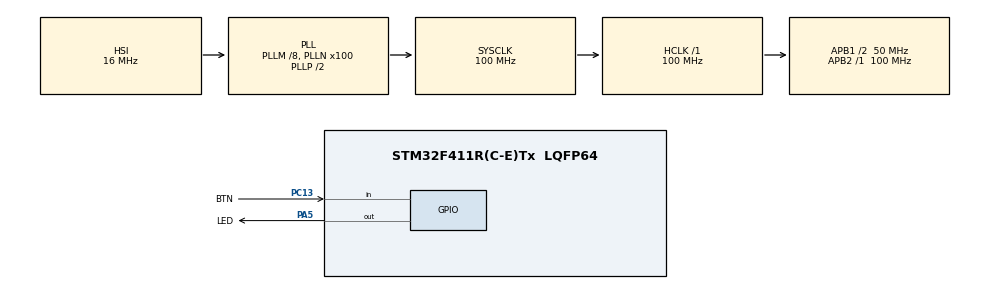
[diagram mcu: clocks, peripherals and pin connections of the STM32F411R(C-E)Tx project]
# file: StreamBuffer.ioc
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FREERTOS.Tasks01=defaultTask,24,128,StartDefaultTask,Default,NULL,Dynamic,NULL,NULL
FREERTOS.configUSE_NEWLIB_REENTRANT=1
Mcu.Family=STM32F4
Mcu.Name=STM32F411R(C-E)Tx
Mcu.Package=LQFP64
NVIC.PriorityGroup=NVIC_PRIORITYGROUP_4
NVIC.TIM1_UP_TIM10_IRQn=true\:15\:0\:false\:false\:true\:false\:false\:true\:true
NVIC.TimeBase=TIM1_UP_TIM10_IRQn
NVIC.TimeBaseIP=TIM1
PA13.Mode=Serial_Wire
PA13.Signal=SYS_JTMS-SWDIO
PA14.Mode=Serial_Wire
PA14.Signal=SYS_JTCK-SWCLK
PA5.GPIO_Label=LED
PA5.Signal=GPIO_Output
PC13-ANTI_TAMP.GPIO_Label=BTN
PC13-ANTI_TAMP.Signal=GPIO_Input
ProjectManager.HeapSize=0x200
ProjectManager.StackSize=0x400
ProjectManager.TargetToolchain=STM32CubeIDE
RCC.48MHZClocksFreq_Value=50000000
RCC.AHBFreq_Value=100000000
RCC.APB1CLKDivider=RCC_HCLK_DIV2
RCC.APB1Freq_Value=50000000
RCC.APB1TimFreq_Value=100000000
RCC.APB2Freq_Value=100000000
RCC.APB2TimFreq_Value=100000000
RCC.CortexFreq_Value=100000000
RCC.HCLKFreq_Value=100000000
RCC.HSE_VALUE=25000000
RCC.HSI_VALUE=16000000
RCC.LSE_VALUE=32768
RCC.PLLM=8
RCC.PLLN=100
RCC.SYSCLKFreq_VALUE=100000000
RCC.SYSCLKSource=RCC_SYSCLKSOURCE_PLLCLK
RCC.VCOOutputFreq_Value=200000000
VP_FREERTOS_VS_CMSIS_V2.Mode=CMSIS_V2
VP_SYS_VS_tim1.Mode=TIM1
board=custom

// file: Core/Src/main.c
/* USER CODE BEGIN Header */
/**
  ******************************************************************************
  * @file           : main.c
  * @brief          : Main program body
  ******************************************************************************
  * @attention
  *
  * Copyright (c) 2025 STMicroelectronics.
  * All rights reserved.
  *
  * This software is licensed under terms that can be found in the LICENSE file
  * in the root directory of this software component.
  * If no LICENSE file comes with this software, it is provided AS-IS.
  *
  ******************************************************************************
  */
/* USER CODE END Header */
#include "main.h"
#include "cmsis_os.h"

/* USER CODE BEGIN Includes */
#include <string.h>
#include <stdio.h>
#include "stream_buffer.h"
/* USER CODE END Includes */

/* Definitions for defaultTask */

/* USER CODE BEGIN PV */
TaskHandle_t task1_handle;
TaskHandle_t task2_handle;
StreamBufferHandle_t sb_handle_task1_to_task2;
StreamBufferHandle_t sb_handle_task2_to_task1;
char task1_buffer[15];
char task2_buffer[15];
uint8_t task1_sended_byte;
uint8_t task1_received_byte;
uint8_t task2_sended_byte;
uint8_t task2_received_byte;

void Task1(void *param);
void Task2(void *param);
/* USER CODE END PV */

void SystemClock_Config(void);
static void MX_GPIO_Init(void);

/* USER CODE BEGIN 0 */
uint8_t cnt = 0;
/* USER CODE END 0 */

int main(void)
{

  /* MCU Configuration--------------------------------------------------------*/

  /* Reset of all peripherals, Initializes the Flash interface and the Systick. */
  HAL_Init();

  /* Configure the system clock */
  SystemClock_Config();

  /* Initialize all configured peripherals */
  MX_GPIO_Init();

  /* Init scheduler */
  osKernelInitialize();

  /* Create the thread(s) */

  /* USER CODE BEGIN RTOS_THREADS */
  /* add threads, ... */

  xTaskCreate(Task1, "Task1", 128, NULL, 1, &task1_handle);
  xTaskCreate(Task2, "Task2", 128, NULL, 2, &task2_handle);
  /* USER CODE END RTOS_THREADS */

  /* Start scheduler */
  vTaskStartScheduler();
  /* We should never get here as control is now taken by the scheduler */

  /* Infinite loop */
  while (1)
  {

  }
}

void SystemClock_Config(void)
{
  RCC_OscInitTypeDef RCC_OscInitStruct = {0};
  RCC_ClkInitTypeDef RCC_ClkInitStruct = {0};

  /** Configure the main internal regulator output voltage
  */
  __HAL_RCC_PWR_CLK_ENABLE();
  __HAL_PWR_VOLTAGESCALING_CONFIG(PWR_REGULATOR_VOLTAGE_SCALE1);

  /** Initializes the RCC Oscillators according to the specified parameters
  * in the RCC_OscInitTypeDef structure.
  */
  RCC_OscInitStruct.OscillatorType = RCC_OSCILLATORTYPE_HSI;
  RCC_OscInitStruct.HSIState = RCC_HSI_ON;
  RCC_OscInitStruct.HSICalibrationValue = RCC_HSICALIBRATION_DEFAULT;
  RCC_OscInitStruct.PLL.PLLState = RCC_PLL_ON;
  RCC_OscInitStruct.PLL.PLLSource = RCC_PLLSOURCE_HSI;
  RCC_OscInitStruct.PLL.PLLM = 8;
  RCC_OscInitStruct.PLL.PLLN = 100;
  RCC_OscInitStruct.PLL.PLLP = RCC_PLLP_DIV2;
  RCC_OscInitStruct.PLL.PLLQ = 4;
  if (HAL_RCC_OscConfig(&RCC_OscInitStruct) != HAL_OK)
  {
    Error_Handler();
  }

  /** Initializes the CPU, AHB and APB buses clocks
  */
  RCC_ClkInitStruct.ClockType = RCC_CLOCKTYPE_HCLK|RCC_CLOCKTYPE_SYSCLK
                              |RCC_CLOCKTYPE_PCLK1|RCC_CLOCKTYPE_PCLK2;
  RCC_ClkInitStruct.SYSCLKSource = RCC_SYSCLKSOURCE_PLLCLK;
  RCC_ClkInitStruct.AHBCLKDivider = RCC_SYSCLK_DIV1;
  RCC_ClkInitStruct.APB1CLKDivider = RCC_HCLK_DIV2;
  RCC_ClkInitStruct.APB2CLKDivider = RCC_HCLK_DIV1;

  if (HAL_RCC_ClockConfig(&RCC_ClkInitStruct, FLASH_LATENCY_3) != HAL_OK)
  {
    Error_Handler();
  }
}

static void MX_GPIO_Init(void)
{
  GPIO_InitTypeDef GPIO_InitStruct = {0};

  /* GPIO Ports Clock Enable */
  __HAL_RCC_GPIOC_CLK_ENABLE();
  __HAL_RCC_GPIOA_CLK_ENABLE();

  /*Configure GPIO pin Output Level */
  HAL_GPIO_WritePin(LED_GPIO_Port, LED_Pin, GPIO_PIN_RESET);

  /*Configure GPIO pin : BTN_Pin */
  GPIO_InitStruct.Pin = BTN_Pin;
  GPIO_InitStruct.Mode = GPIO_MODE_INPUT;
  GPIO_InitStruct.Pull = GPIO_NOPULL;
  HAL_GPIO_Init(BTN_GPIO_Port, &GPIO_InitStruct);

  /*Configure GPIO pin : LED_Pin */
  GPIO_InitStruct.Pin = LED_Pin;
  GPIO_InitStruct.Mode = GPIO_MODE_OUTPUT_PP;
  GPIO_InitStruct.Pull = GPIO_NOPULL;
  GPIO_InitStruct.Speed = GPIO_SPEED_FREQ_LOW;
  HAL_GPIO_Init(LED_GPIO_Port, &GPIO_InitStruct);

}

/* USER CODE BEGIN 4 */
void Task1(void *param){

	sb_handle_task1_to_task2 = xStreamBufferCreate(15, 1);
	char txbuff[10] = {"\0"};
	uint8_t cnt = 0;
	uint32_t prev_time = 0;
	while(1)
	{
		if(((xTaskGetTickCount() * (1000/configTICK_RATE_HZ)) - prev_time) > 500){
			cnt++;
			sprintf(txbuff,"task1:%3d", cnt);
			task1_sended_byte = xStreamBufferSend(sb_handle_task1_to_task2, txbuff, strlen(txbuff), pdMS_TO_TICKS(1000));
			prev_time = (xTaskGetTickCount() * (1000/configTICK_RATE_HZ));
		}
		task1_received_byte =  xStreamBufferReceive(sb_handle_task2_to_task1, task1_buffer, 9, pdMS_TO_TICKS(50));

		vTaskDelay(1);
	}
}

void Task2(void *param){
	sb_handle_task2_to_task1 = xStreamBufferCreate(15, 1);
	char txbuff[10] = {"\0"};
	uint8_t cnt = 0;
	uint32_t prev_time = 0;
	while(1)
	{
		if(((xTaskGetTickCount() * (1000/configTICK_RATE_HZ)) - prev_time) > 500){
			cnt++;
			sprintf(txbuff,"task2:%3d", cnt);
			task2_sended_byte = xStreamBufferSend(sb_handle_task2_to_task1, txbuff, strlen(txbuff), pdMS_TO_TICKS(50));
			prev_time = (xTaskGetTickCount() * (1000/configTICK_RATE_HZ));
		}
		vTaskDelay(1000);
		task2_received_byte =  xStreamBufferReceive(sb_handle_task1_to_task2, task2_buffer, 9, pdMS_TO_TICKS(50));

	}
}
/* USER CODE END 4 */

void HAL_TIM_PeriodElapsedCallback(TIM_HandleTypeDef *htim)
{
  if (htim->Instance == TIM1)
  {
    HAL_IncTick();
  }
}

void Error_Handler(void)
{
  __disable_irq();
  while (1)
  {
  }
}
